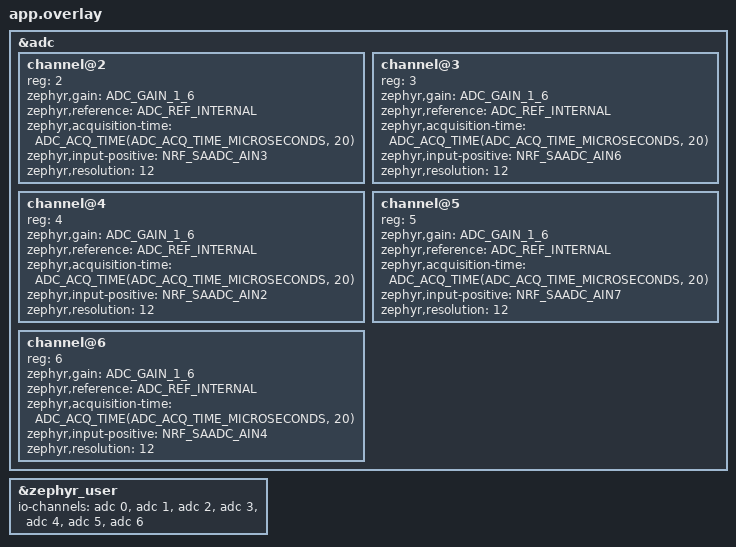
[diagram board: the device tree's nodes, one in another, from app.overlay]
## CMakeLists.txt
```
cmake_minimum_required(VERSION 3.20.0)
find_package(Zephyr REQUIRED HINTS $ENV{ZEPHYR_BASE})
project(sp1verb)
include(${ZEPHYR_BASE}/samples/subsys/usb/common/common.cmake)
target_sources(app PRIVATE src/main.c ../fx/fx.c)
target_include_directories(app PRIVATE ../fx)
# The effects engine is float math in the audio thread: build it for speed. The rest stays -Os.
# -ffp-contract=off: on the Cortex-M4 a fused VFMA takes 3 cycles, VMUL + VADD take 2.
set_source_files_properties(../fx/fx.c PROPERTIES COMPILE_OPTIONS "-O2;-fno-math-errno;-ffp-contract=off;-fno-strict-aliasing")
```

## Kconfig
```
# SP-1FX firmware application Kconfig.
#
# Pulls in the common USB sample options (CONFIG_SAMPLE_USBD_VID/PID/PRODUCT/...)
# consumed by the vendored sample_usbd_init.c device_next bring-up helper, then
# the standard Zephyr Kconfig tree.

source "samples/subsys/usb/common/Kconfig.sample_usbd"

source "Kconfig.zephyr"
```

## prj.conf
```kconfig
# SP-1FX: Zephyr configuration. Based on chattock/sp1-tape-looper's (MIT), which runs on SP-1
# hardware; the eMMC, MIDI and looper parts are gone.
CONFIG_LOG=n
CONFIG_ASSERT=n
CONFIG_IDLE_STACK_SIZE=128
CONFIG_ISR_STACK_SIZE=1024
CONFIG_WATCHDOG=y

# a fatal fault becomes a reboot (k_sys_fatal_error_handler); the watchdog backs up a hang
CONFIG_HW_STACK_PROTECTION=n
CONFIG_STACK_SENTINEL=y
CONFIG_REBOOT=y
CONFIG_CLOCK_CONTROL=y
CONFIG_CLOCK_CONTROL_NRF_K32SRC_SYNTH=y

# USB serial console (CDC ACM) for the status line
CONFIG_PRINTK=y
CONFIG_SERIAL=y
CONFIG_CONSOLE=y
CONFIG_UART_CONSOLE=y
CONFIG_UART_LINE_CTRL=y
CONFIG_UART_INTERRUPT_DRIVEN=y

# USB-C audio: UAC2 (class compliant) + CDC ACM, composite, on the device_next stack
CONFIG_USB_DEVICE_STACK_NEXT=y
CONFIG_USBD_AUDIO2_CLASS=y
CONFIG_USBD_CDC_ACM_CLASS=y
CONFIG_CDC_ACM_SERIAL_INITIALIZE_AT_BOOT=n
CONFIG_HWINFO=y
CONFIG_SAMPLE_USBD_VID=0x1915
CONFIG_SAMPLE_USBD_PID=0x5211
CONFIG_SAMPLE_USBD_MANUFACTURER="softmodded"
CONFIG_SAMPLE_USBD_PRODUCT="SP-1 Reverb"
# As the looper (and earlier builds that worked on Linux handhelds): 4-byte feedback endpoint for
# Windows, value sent as the standard 3-byte Q10.14 that Linux and macOS read
CONFIG_USBD_UAC2_FS_WINDOWS_WORKAROUND=y
# 16-bit (alternate 1, what Linux handhelds open) and 24-bit (alternate 2); see usbd_uac2.c
CONFIG_USBD_UAC2_SP1_ALT24=y
CONFIG_THREAD_RUNTIME_STATS=n
CONFIG_SCHED_THREAD_USAGE=n
# iOS camera adapters refuse accessories over 100 mA
CONFIG_SAMPLE_USBD_MAX_POWER=50

CONFIG_ADC=y
CONFIG_I2C=y
CONFIG_I2S=y
CONFIG_I2S_NRFX=y
CONFIG_FPU=y
CONFIG_FPU_SHARING=y

CONFIG_MAIN_STACK_SIZE=2048
CONFIG_THREAD_STACK_INFO=y
```

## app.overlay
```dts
/* SP-1FX: the faders and the battery on the SAADC (channels 0 and 1, the button ladders, are in
 * the board file). Same settings as the button ladders: gain 1/6, internal reference, 12-bit, so a
 * fader reads about 0 (down) to 3700 (up). From chattock/sp1-tape-looper (MIT). */
#include <zephyr/dt-bindings/adc/adc.h>
#include <zephyr/dt-bindings/adc/nrf-saadc.h>

&adc {
	channel@2 { reg = <2>; zephyr,gain = "ADC_GAIN_1_6"; zephyr,reference = "ADC_REF_INTERNAL";
		zephyr,acquisition-time = <ADC_ACQ_TIME(ADC_ACQ_TIME_MICROSECONDS, 20)>;
		zephyr,input-positive = <NRF_SAADC_AIN3>; zephyr,resolution = <12>; };   /* Fader 1 P0.05 */
	channel@3 { reg = <3>; zephyr,gain = "ADC_GAIN_1_6"; zephyr,reference = "ADC_REF_INTERNAL";
		zephyr,acquisition-time = <ADC_ACQ_TIME(ADC_ACQ_TIME_MICROSECONDS, 20)>;
		zephyr,input-positive = <NRF_SAADC_AIN6>; zephyr,resolution = <12>; };   /* Fader 2 P0.30 */
	channel@4 { reg = <4>; zephyr,gain = "ADC_GAIN_1_6"; zephyr,reference = "ADC_REF_INTERNAL";
		zephyr,acquisition-time = <ADC_ACQ_TIME(ADC_ACQ_TIME_MICROSECONDS, 20)>;
		zephyr,input-positive = <NRF_SAADC_AIN2>; zephyr,resolution = <12>; };   /* Fader 3 P0.04 */
	channel@5 { reg = <5>; zephyr,gain = "ADC_GAIN_1_6"; zephyr,reference = "ADC_REF_INTERNAL";
		zephyr,acquisition-time = <ADC_ACQ_TIME(ADC_ACQ_TIME_MICROSECONDS, 20)>;
		zephyr,input-positive = <NRF_SAADC_AIN7>; zephyr,resolution = <12>; };   /* Fader 4 P0.31 */
	channel@6 { reg = <6>; zephyr,gain = "ADC_GAIN_1_6"; zephyr,reference = "ADC_REF_INTERNAL";
		zephyr,acquisition-time = <ADC_ACQ_TIME(ADC_ACQ_TIME_MICROSECONDS, 20)>;
		zephyr,input-positive = <NRF_SAADC_AIN4>; zephyr,resolution = <12>; };   /* Battery P0.28 */
};
&zephyr_user {
	io-channels = <&adc 0>, <&adc 1>, <&adc 2>, <&adc 3>, <&adc 4>, <&adc 5>, <&adc 6>;
};
```

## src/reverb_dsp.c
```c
/**
 * SP-1 Early Digital Reverb DSP Core Implementation in C
 * Target: Nordic nRF52840 (ARM Cortex-M4F @ 64MHz, 256KB RAM)
 * 
 * Implements:
 * 1. Pre-delay with circular buffer
 * 2. 12-bit / 8-bit DAC quantizer & soft-saturator
 * 3. 3-stage input diffusion all-pass chain
 * 4. Dual cross-coupled modulated delay tanks with 1-pole damping lowpass filters
 * 5. Sinusoidal LFO for tank wander chorusing
 * 6. Dry/Wet constant power matrix
 */

#include "reverb_dsp.h"
#include <math.h>
#include <string.h>

#define PRE_DELAY_MAX_SAMPLES 6000 // 250ms at 24kHz
#define DIFF1_LEN 113  // ~4.7ms
#define DIFF2_LEN 223  // ~9.3ms
#define DIFF3_LEN 307  // ~12.7ms
#define TANK_L_LEN 3408 // ~142ms
#define TANK_R_LEN 4032 // ~168ms
#define TANK_DIFF_L_LEN 720  // ~30ms
#define TANK_DIFF_R_LEN 936  // ~39ms

// Audio buffers allocated in SRAM
static float s_pre_delay_buf[PRE_DELAY_MAX_SAMPLES];
static uint32_t s_pre_delay_idx = 0;

// All-pass buffers
static float s_diff1_buf[DIFF1_LEN];
static uint32_t s_diff1_idx = 0;
static float s_diff2_buf[DIFF2_LEN];
static uint32_t s_diff2_idx = 0;
static float s_diff3_buf[DIFF3_LEN];
static uint32_t s_diff3_idx = 0;

// Tank Buffers
static float s_tank_l_buf[TANK_L_LEN];
static uint32_t s_tank_l_idx = 0;
static float s_tank_r_buf[TANK_R_LEN];
static uint32_t s_tank_r_idx = 0;

static float s_tank_diff_l_buf[TANK_DIFF_L_LEN];
static uint32_t s_tank_diff_l_idx = 0;
static float s_tank_diff_r_buf[TANK_DIFF_R_LEN];
static uint32_t s_tank_diff_r_idx = 0;

// Filter state
static float s_lp_state_l = 0.0f;
static float s_lp_state_r = 0.0f;
static float s_hp_state_l = 0.0f;
static float s_hp_state_r = 0.0f;

// LFO Phase
static float s_lfo_phase = 0.0f;

static sp1_reverb_params_t s_params;

// 8 Historic Early Digital Presets
const sp1_preset_t g_sp1_presets[SP1_NUM_PRESETS] = {
    { "224 Concert Hall", 1978, { 0.45f, 5.2f, 0.82f, 5800.0f, 0, 0.65f, 0.75f, 32.0f, 0.35f, false, 0 } },
    { "EMT 250 Space Plate", 1976, { 0.50f, 3.4f, 0.70f, 4600.0f, 0, 0.45f, 0.60f, 18.0f, 0.55f, false, 0 } },
    { "RMX Non-Lin Snare", 1981, { 0.60f, 1.4f, 0.90f, 8200.0f, 1, 0.20f, 1.20f, 12.0f, 0.40f, false, 0 } },
    { "DRE-2000 Clean Room", 1980, { 0.35f, 2.2f, 0.85f, 9500.0f, 0, 0.30f, 0.45f, 20.0f, 0.15f, false, 0 } },
    { "Space Station SST-282", 1978, { 0.55f, 7.0f, 0.38f, 3800.0f, 0, 0.80f, 1.60f, 45.0f, 0.75f, false, 0 } },
    { "Blade Runner Wash", 1982, { 0.65f, 16.5f, 0.95f, 3200.0f, 0, 0.88f, 0.50f, 60.0f, 0.45f, false, 0 } },
    { "80s Dark Cathedral", 1983, { 0.50f, 11.2f, 0.78f, 2400.0f, 0, 0.50f, 0.35f, 75.0f, 0.30f, false, 0 } },
    { "12-Bit Vintage Chamber", 1979, { 0.50f, 3.8f, 0.52f, 5200.0f, 1, 0.70f, 1.10f, 25.0f, 0.85f, false, 0 } },
};

void sp1_reverb_init(void) {
    memset(s_pre_delay_buf, 0, sizeof(s_pre_delay_buf));
    memset(s_diff1_buf, 0, sizeof(s_diff1_buf));
    memset(s_diff2_buf, 0, sizeof(s_diff2_buf));
    memset(s_diff3_buf, 0, sizeof(s_diff3_buf));
    memset(s_tank_l_buf, 0, sizeof(s_tank_l_buf));
    memset(s_tank_r_buf, 0, sizeof(s_tank_r_buf));
    memset(s_tank_diff_l_buf, 0, sizeof(s_tank_diff_l_buf));
    memset(s_tank_diff_r_buf, 0, sizeof(s_tank_diff_r_buf));
    s_pre_delay_idx = 0;
    s_diff1_idx = s_diff2_idx = s_diff3_idx = 0;
    s_tank_l_idx = s_tank_r_idx = 0;
    s_tank_diff_l_idx = s_tank_diff_r_idx = 0;
    s_lp_state_l = s_lp_state_r = 0.0f;
    s_hp_state_l = s_hp_state_r = 0.0f;
    s_lfo_phase = 0.0f;

    sp1_reverb_load_preset(0);
}

void sp1_reverb_set_params(const sp1_reverb_params_t* params) {
    if (params) {
        s_params = *params;
    }
}

void sp1_reverb_load_preset(uint8_t preset_index) {
    if (preset_index >= SP1_NUM_PRESETS) preset_index = 0;
    s_params = g_sp1_presets[preset_index].params;
}

// Inline All-pass filter step
static inline float allpass_step(float in, float* buf, uint32_t* idx, uint32_t len, float gain) {
    float buf_out = buf[*idx];
    float new_buf = in + gain * buf_out;
    buf[*idx] = new_buf;
    *idx = (*idx + 1) % len;
    return -gain * new_buf + buf_out;
}

// Vintage 12-bit DAC decimation & soft tanh saturation
static inline float vintage_dac_grit(float in, float grit) {
    if (grit <= 0.01f) return in;
    float bits = 16.0f - grit * 8.0f; // 16-bit down to 8-bit
    float steps = powf(2.0f, bits);
    float driven = in * (1.0f + grit * 0.8f);
    float quantized = roundf(driven * (steps * 0.5f)) / (steps * 0.5f);
    // Fast tanh approximation
    float x = quantized;
    float x2 = x * x;
    return x * (27.0f + x2) / (27.0f + 9.0f * x2);
}

void sp1_reverb_process_block(const int16_t* in_stereo, int16_t* out_stereo, uint32_t num_frames) {
    float dry_gain = cosf(s_params.mix * 1.5707963f);
    float wet_gain = sinf(s_params.mix * 1.5707963f);
    float diff_gain = 0.70f * s_params.diffusion;

    // Feedback gain from RT60 decay time
    float fb = s_params.freeze ? 0.999f : powf(0.001f, 0.155f / fmaxf(0.1f, s_params.decay));
    if (fb > 0.96f) fb = 0.96f;

    // Damping LP filter coefficient
    float fc_norm = s_params.filter_cutoff / (float)SP1_SAMPLE_RATE;
    float alpha = fminf(0.95f, fmaxf(0.05f, 2.0f * 3.14159f * fc_norm));

    // Pre-delay in samples
    uint32_t pre_delay_samples = (uint32_t)((s_params.pre_delay_ms / 1000.0f) * SP1_SAMPLE_RATE);
    if (pre_delay_samples >= PRE_DELAY_MAX_SAMPLES) pre_delay_samples = PRE_DELAY_MAX_SAMPLES - 1;

    float lfo_inc = (2.0f * 3.14159265f * s_params.mod_rate) / (float)SP1_SAMPLE_RATE;
    float mod_depth_samples = s_params.mod_depth * 80.0f; // up to ~3.3ms modulation

    for (uint32_t i = 0; i < num_frames; i++) {
        // Convert input from 16-bit int to float [-1.0, 1.0]
        float in_l = (float)in_stereo[i * 2] / 32768.0f;
        float in_r = (float)in_stereo[i * 2 + 1] / 32768.0f;
        float mono_in = (in_l + in_r) * 0.5f;

        // 1. Pre-delay
        s_pre_delay_buf[s_pre_delay_idx] = mono_in;
        uint32_t read_idx = (s_pre_delay_idx + PRE_DELAY_MAX_SAMPLES - pre_delay_samples) % PRE_DELAY_MAX_SAMPLES;
        float delayed_in = s_pre_delay_buf[read_idx];
        s_pre_delay_idx = (s_pre_delay_idx + 1) % PRE_DELAY_MAX_SAMPLES;

        // 2. Vintage DAC Grit
        float gritted = vintage_dac_grit(delayed_in, s_params.vintage_grit);

        // 3. Input Diffusion Cascade (3 All-pass stages)
        float d1 = allpass_step(gritted, s_diff1_buf, &s_diff1_idx, DIFF1_LEN, diff_gain);
        float d2 = allpass_step(d1, s_diff2_buf, &s_diff2_idx, DIFF2_LEN, diff_gain);
        float diffused = allpass_step(d2, s_diff3_buf, &s_diff3_idx, DIFF3_LEN, diff_gain);

        // 4. LFO Wander
        s_lfo_phase += lfo_inc;
        if (s_lfo_phase > 6.2831853f) s_lfo_phase -= 6.2831853f;
        float lfo_val = sinf(s_lfo_phase);
        float mod_offset = lfo_val * mod_depth_samples;

        // 5. Left Tank
        uint32_t read_tank_l = (uint32_t)((float)s_tank_l_idx + TANK_L_LEN - 1 + mod_offset) % TANK_L_LEN;
        float tank_out_l = s_tank_l_buf[read_tank_l];
        float diff_out_l = allpass_step(tank_out_l, s_tank_diff_l_buf, &s_tank_diff_l_idx, TANK_DIFF_L_LEN, 0.6f * s_params.diffusion);
        
        // One-pole Damping Lowpass Filter
        s_lp_state_l += alpha * (diff_out_l - s_lp_state_l);
        // Anti-rumble Highpass (50Hz)
        s_hp_state_l = 0.985f * (s_hp_state_l + s_lp_state_l - s_lp_state_l);

        // 6. Right Tank
        uint32_t read_tank_r = (uint32_t)((float)s_tank_r_idx + TANK_R_LEN - 1 - mod_offset) % TANK_R_LEN;
        float tank_out_r = s_tank_r_buf[read_tank_r];
        float diff_out_r = allpass_step(tank_out_r, s_tank_diff_r_buf, &s_tank_diff_r_idx, TANK_DIFF_R_LEN, 0.6f * s_params.diffusion);
        
        s_lp_state_r += alpha * (diff_out_r - s_lp_state_r);
        s_hp_state_r = 0.985f * (s_hp_state_r + s_lp_state_r - s_lp_state_r);

        // Cross-coupled feedback into tanks
        s_tank_l_buf[s_tank_l_idx] = diffused + fb * (0.7f * s_lp_state_l + 0.3f * s_lp_state_r);
        s_tank_r_buf[s_tank_r_idx] = diffused + fb * (0.7f * s_lp_state_r + 0.3f * s_lp_state_l);

        s_tank_l_idx = (s_tank_l_idx + 1) % TANK_L_LEN;
        s_tank_r_idx = (s_tank_r_idx + 1) % TANK_R_LEN;

        // 7. Wet / Dry Mix Matrix
        float wet_l = s_lp_state_l;
        float wet_r = s_lp_state_r;
        float final_l = in_l * dry_gain + wet_l * wet_gain;
        float final_r = in_r * dry_gain + wet_r * wet_gain;

        // Hard clip protection [-1.0, 1.0] and convert back to 16-bit
        final_l = fmaxf(-1.0f, fminf(1.0f, final_l));
        final_r = fmaxf(-1.0f, fminf(1.0f, final_r));

        out_stereo[i * 2]     = (int16_t)(final_l * 32767.0f);
        out_stereo[i * 2 + 1] = (int16_t)(final_r * 32767.0f);
    }
}
```

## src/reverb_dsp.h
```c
/**
 * SP-1 Early Digital Reverb DSP Header for Nordic nRF52840 (ARM Cortex-M4F @ 64MHz)
 * Schroeder-Dattorro topology with vintage 12-bit DAC decimation and cross-coupled delay tanks.
 */

#ifndef SP1_REVERB_DSP_H
#define SP1_REVERB_DSP_H

#include <stdint.h>
#include <stdbool.h>

#define SP1_SAMPLE_RATE 24000
#define SP1_NUM_PRESETS 8

typedef struct {
    // Bank A: Core Controls (1-4)
    float mix;             // 0.0 to 1.0 (Dry/Wet)
    float decay;           // 0.2 to 25.0 seconds
    float diffusion;       // 0.0 to 1.0 (All-pass smearing)
    float filter_cutoff;   // 200.0 to 16000.0 Hz
    uint8_t filter_mode;   // 0: Low-pass, 1: Band-pass, 2: High-pass

    // Bank B: Tone Modulation Controls (Switched on PLAY)
    float mod_depth;       // 0.0 to 1.0 (Tank wander chorus)
    float mod_rate;        // 0.1 to 6.0 Hz (LFO spin)
    float pre_delay_ms;    // 0 to 250 ms
    float vintage_grit;    // 0.0 to 1.0 (12-bit / 8-bit DAC decimation)

    // Hardware flags
    bool freeze;
    uint8_t active_bank;   // 0: Bank A (Core), 1: Bank B (Mod)
} sp1_reverb_params_t;

typedef struct {
    const char* name;
    uint16_t year;
    sp1_reverb_params_t params;
} sp1_preset_t;

// DSP Engine API
void sp1_reverb_init(void);
void sp1_reverb_set_params(const sp1_reverb_params_t* params);
void sp1_reverb_load_preset(uint8_t preset_index);
void sp1_reverb_process_block(const int16_t* in_stereo, int16_t* out_stereo, uint32_t num_frames);

extern const sp1_preset_t g_sp1_presets[SP1_NUM_PRESETS];

#endif // SP1_REVERB_DSP_H
```
